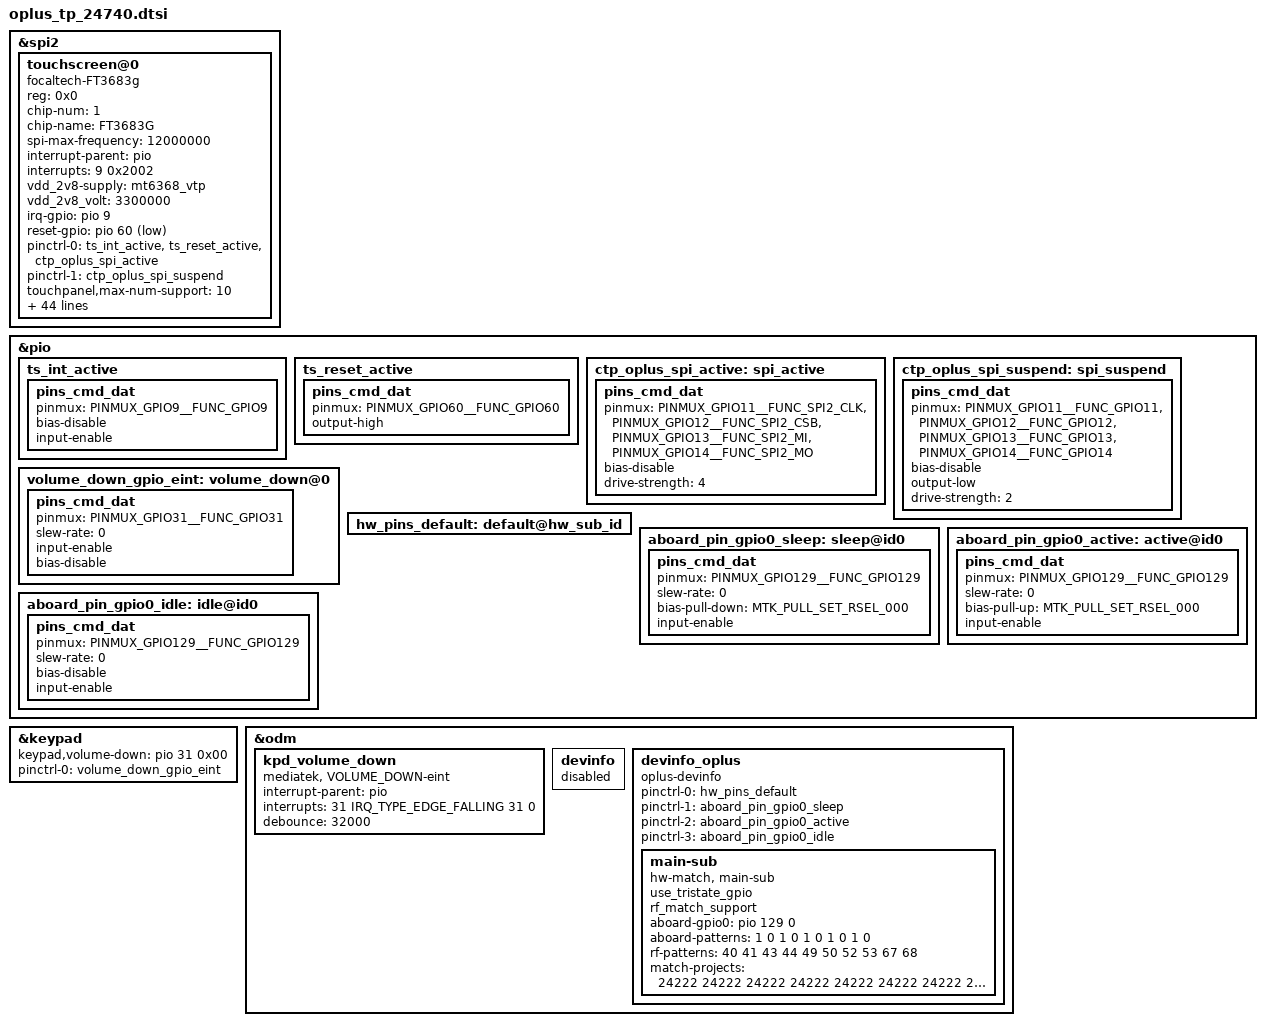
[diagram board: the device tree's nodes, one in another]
&spi2 {
	status = "okay";
	#address-cells = <1>;
	#size-cells = <0>;

	touchscreen@0{
		compatible = "focaltech-FT3683g";
		reg = <0x0>;
		chip-num = <1>;
		chip-name = "FT3683G";
		status = "okay";
		spi-max-frequency = <12000000>;
		/* Interrupt && Irq-gpio */
		interrupt-parent = <&pio>;
		interrupts = <9 0x2002>;

		/* Power Config */
		//vcc_1v8-supply  = <&mt6369_vant18>;
		//vcc_1v8_volt = <1800000>;
		vdd_2v8-supply  = <&mt6368_vtp>;
		vdd_2v8_volt = <3300000>;


		/* Other HW Resource */

		irq-gpio = <&pio 9 0x2002>;
		reset-gpio = <&pio 60 0x1>;

		pinctrl-names = "default",  "sleep";
		pinctrl-0 = <&ts_int_active &ts_reset_active &ctp_oplus_spi_active>;
		pinctrl-1 = <&ctp_oplus_spi_suspend>;

		touchpanel,max-num-support = <10>;
		touchpanel,tx-rx-num = <18 40>;
		touchpanel,panel-coords = <20352 44800>;
		touchpanel,display-coords = <1272 2800>;
		touchpanel,touchmajor-limit = <128 216>;
		//touchpanel,elimination-range = <20 200 200>;
		//touchpanel,int-mode = <1>; /*0: interrupt and disable, 1:interrupt and not disable*/
		touchpanel,smooth-level = <0 110 115 120 140 155>;
		touchpanel,smooth-level-charging = <0 110 115 120 140 155>;
		touchpanel,sensitive-level = <0 19 16 12 11 10>;
		touchpanel,tp-index = <0>;
		touchpanel,high-frame-rate-time = <60>;
		disable_suspend_irq_handler_support;

		vid_len = <2>;
		firmware_name = "AB913TF";
		panel_type = <7>; /* panel-TM*/
		platform_support_project = <24740 24742>;
		platform_support_project_dir = <24740 24742>;
		platform_support_project_commandline = "panel_ae016_p_7_a0014_dsi_cmd-focaltech-FT3683g";


		/*
		 *Virtual Key Config:
		 *1:touchpanel,button-type: <virtualkey_type  supportted_button-map>
		 *virtualkey_type:
		 *Type 1: using board_properties
		 *Type 2: using same IC (button zone&& touch zone are seprate)
		 *Type 3: using diffrent IC (button zone&& touch zone are seprate)
		 *Type 4: No need of virtual key process
		 *supportted_button-map:select|menu|home|back
		 *
		 *2:touchpanel,button-map
		 *type (X1,Y1)(X2,Y2)(X3,Y3)(Width_X,Hight_Y)--Only when button-type is 0
		 */
		touchpanel,button-type = <4>;
		touchpanel.button-TRx = <0 0>;

		health_monitor_v2_support;
		black_gesture_support;
		charger_pump_support;
		lcd_tp_refresh_support;
		fw_update_app_support;
		smart_gesture_support;
		game_switch_support;
		report_flow_unlock_support;
		fingerprint_underscreen_support;
		pressure_report_support;
		touchpanel,single-optimized-time = <8>;
		//report_rate_white_list_support;
		auto_test_force_pass_support;
		snr_read_support;
		//high_resolution_support;
		screenoff_fingerprint_info_support;
		irq_need_dev_resume_ok;
		sportify_aod_gesture_support;
		black_gesture_indep_support;
		thermal_detect_support;
		exception_upload_support;
		tp_data_record_support;
		palm_to_sleep_support;
		glove_mode_v2_support;
		freq_hop_simulate_support;
		fw_edge_limit_support;
	};
};

&pio {
	ts_int_active: ts_int_active {
		pins_cmd_dat {
			pinmux = <PINMUX_GPIO9__FUNC_GPIO9>;
			bias-disable;
			input-enable;
		};
	};
	ts_reset_active: ts_reset_active {
		pins_cmd_dat {
			pinmux = <PINMUX_GPIO60__FUNC_GPIO60>;
			output-high;
		};
	};
	ctp_oplus_spi_active: spi_active {
		pins_cmd_dat {
			pinmux = <PINMUX_GPIO11__FUNC_SPI2_CLK>,
				<PINMUX_GPIO12__FUNC_SPI2_CSB>,
				<PINMUX_GPIO13__FUNC_SPI2_MI>,
				<PINMUX_GPIO14__FUNC_SPI2_MO>;
			bias-disable;
			drive-strength = <4>;
		};
	};
	ctp_oplus_spi_suspend: spi_suspend {
		pins_cmd_dat {
			pinmux = <PINMUX_GPIO11__FUNC_GPIO11>,
					<PINMUX_GPIO12__FUNC_GPIO12>,
					<PINMUX_GPIO13__FUNC_GPIO13>,
					<PINMUX_GPIO14__FUNC_GPIO14>;
			bias-disable;
			output-low;
			drive-strength = <2>;
		};
	};
};

&keypad {
        keypad,volume-down = <&pio 31 0x00>;
        pinctrl-names = "volume_down_as_int";
        pinctrl-0 = <&volume_down_gpio_eint>;
        status = "okay";
};

&pio {
        volume_down_gpio_eint:volume_down@0{
                pins_cmd_dat {
                        pinmux = <PINMUX_GPIO31__FUNC_GPIO31>;
                        slew-rate = <0>;  /*direction 0:in, 1:out*/
                        input-enable;
                        bias-disable;
                };
        };
};

&odm {
        kpd_volume_down:kpd_volume_down {
                compatible = "mediatek, VOLUME_DOWN-eint";
                interrupt-parent = <&pio>;
                interrupts = <31 IRQ_TYPE_EDGE_FALLING 31 0>;
                debounce = <32000>;
                status = "okay";
        };
};

&odm {
	devinfo {
		status = "disabled";
	};

	devinfo_oplus {
		compatible = "oplus-devinfo";

		pinctrl-names = "default", "aboard_gpio0_sleep", "aboard_gpio0_active", "aboard_gpio0_idle";
		pinctrl-0 = <&hw_pins_default>;
		pinctrl-1 = <&aboard_pin_gpio0_sleep>;
		pinctrl-2 = <&aboard_pin_gpio0_active>;
		pinctrl-3 = <&aboard_pin_gpio0_idle>;

		main-sub {
			compatible = "hw-match, main-sub";
			use_tristate_gpio;
			rf_match_support;
			aboard-gpio0 = <&pio 129 0>;
			aboard-patterns = <1 0 1 0 1 0 1 0 1 0>;	/*0[high-resistance] 1[pull-down] 2[pull-up]*/
			rf-patterns = <40 41 43 44 49 50 52 53 67 68 >;
			/*main board*/
			match-projects = <24222 24222 24222 24222 24222 24222 24222 24222 24222 24222>;
		};
	};
};

&pio{
	hw_pins_default:default@hw_sub_id {
	};

	aboard_pin_gpio0_sleep:sleep@id0 {
		pins_cmd_dat {
			pinmux = <PINMUX_GPIO129__FUNC_GPIO129>;
			slew-rate = <0>;
			bias-pull-down = <MTK_PULL_SET_RSEL_000>;
			input-enable;
		};
	};

	aboard_pin_gpio0_active:active@id0 {
		pins_cmd_dat {
			pinmux = <PINMUX_GPIO129__FUNC_GPIO129>;
			slew-rate = <0>;
			bias-pull-up = <MTK_PULL_SET_RSEL_000>;
			input-enable;
		};
	};

	aboard_pin_gpio0_idle:idle@id0 {
		pins_cmd_dat {
			pinmux = <PINMUX_GPIO129__FUNC_GPIO129>;
			slew-rate = <0>;
			bias-disable;
			input-enable;
		};
	};
};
